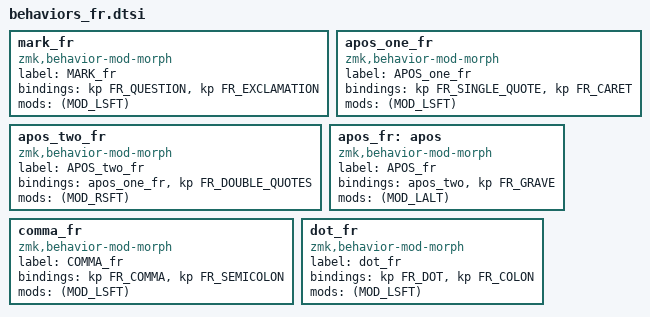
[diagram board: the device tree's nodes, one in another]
// key lshift rshift alt
//  ?     !          
mark_fr: mark_fr {
    compatible = "zmk,behavior-mod-morph";
    label = "MARK_fr";
    #binding-cells = <0>;
    bindings = <&kp FR_QUESTION>, <&kp FR_EXCLAMATION>;
    mods = <(MOD_LSFT)>;
};

// key lshift rshift alt
//  '     ^      "    `
apos_one_fr: apos_one_fr {
    compatible = "zmk,behavior-mod-morph";
    label = "APOS_one_fr";
    #binding-cells = <0>;
    bindings = <&kp FR_SINGLE_QUOTE>, <&kp FR_CARET>;
    mods = <(MOD_LSFT)>;
};
apos_two_fr: apos_two_fr {
    compatible = "zmk,behavior-mod-morph";
    label = "APOS_two_fr";
    #binding-cells = <0>;
    bindings = <&apos_one_fr>, <&kp FR_DOUBLE_QUOTES>;
    mods = <(MOD_RSFT)>;
};
apos_fr: apos {
    compatible = "zmk,behavior-mod-morph";
    label = "APOS_fr";
    #binding-cells = <0>;
    bindings = <&apos_two>, <&kp FR_GRAVE>;
    mods = <(MOD_LALT)>;
};

// key lshift rshift alt
//  ,     ;          
comma_fr: comma_fr {
    compatible = "zmk,behavior-mod-morph";
    label = "COMMA_fr";
    #binding-cells = <0>;
    bindings = <&kp FR_COMMA>, <&kp FR_SEMICOLON>;
    mods = <(MOD_LSFT)>;
};

// key lshift rshift alt
//  .     :          
dot_fr: dot_fr {
    compatible = "zmk,behavior-mod-morph";
    label = "dot_fr";
    #binding-cells = <0>;
    bindings = <&kp FR_DOT>, <&kp FR_COLON>;
    mods = <(MOD_LSFT)>;
};
